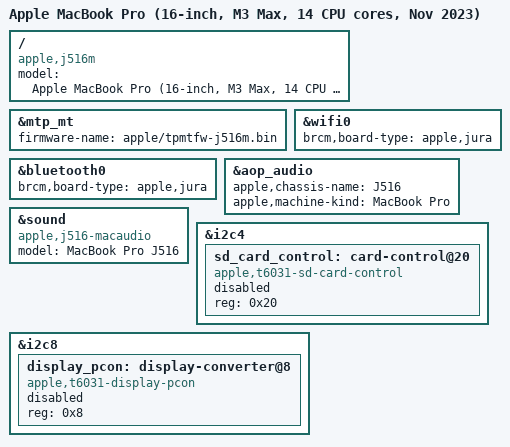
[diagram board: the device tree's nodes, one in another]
// SPDX-License-Identifier: GPL-2.0+ OR MIT
/*
 * MacBook Pro (16-inch, M3 Max, 14 CPU cores, Nov 2023)
 *
 * target-type: J516m
 *
 * Copyright The Asahi Linux Contributors
 */

/dts-v1/;

#include "t6034.dtsi"
#include "t603x-j514-j516.dtsi"

/ {
	compatible = "apple,j516m", "apple,t6034", "apple,arm-platform";
	model = "Apple MacBook Pro (16-inch, M3 Max, 14 CPU cores, Nov 2023)";
};

&mtp_mt {
	firmware-name = "apple/tpmtfw-j516m.bin";
};

&wifi0 {
	brcm,board-type = "apple,jura";
};

&bluetooth0 {
	brcm,board-type = "apple,jura";
};

&aop_audio {
	apple,chassis-name = "J516";
	apple,machine-kind = "MacBook Pro";
};

&sound {
	compatible = "apple,j516-macaudio", "apple,j316-macaudio", "apple,macaudio";
	model = "MacBook Pro J516";
};

&i2c4 {
	sd_card_control: card-control@20 {
		compatible = "apple,t6031-sd-card-control", "apple,sd-card-control";
		reg = <0x20>;
		status = "disabled";
	};
};

&i2c8 {
	display_pcon: display-converter@8 {
		compatible = "apple,t6031-display-pcon", "apple,display-pcon";
		reg = <0x8>;
		status = "disabled";
	};
};
